# STM32H743 register map
File version: 2.4
CPU: CM7 r0p1, little endian, MPU, FPU, 4 interrupt priority bits
Registers are 32-bit, read-write, reset 0x0 unless marked. A register's access mark holds for its fields unless they carry their own. Offsets are from the block's base; [hi:lo] are bit positions.

## QUADSPI
Base 0x52005000
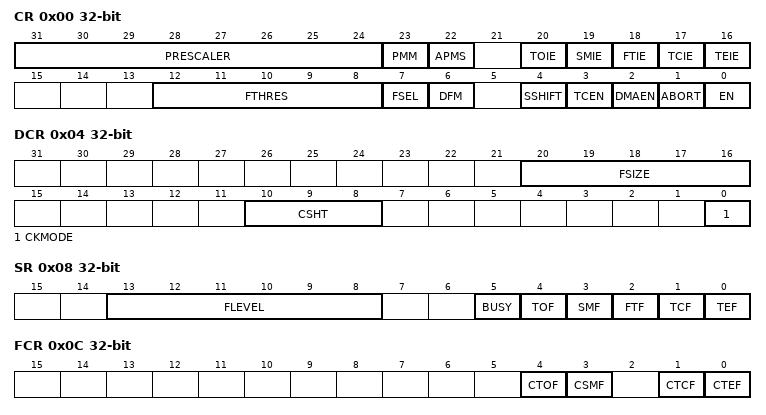
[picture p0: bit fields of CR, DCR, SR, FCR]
0x00 CR — QUADSPI 控制寄存器
  [31:24] PRESCALER — 时钟预分频器
  [23] PMM — 轮询匹配模式 该位指示在自动轮询模式期间用于确定匹配的方法。该位只能在 BUSY = 0 时修改。
  [22] APMS — 自动轮询模式停止 该位决定匹配后是否停止自动轮询。该位只能在 BUSY = 0 时修改。
  [20] TOIE — 超时中断使能 该位使能超时中断。
  [19] SMIE — 状态匹配中断使能 该位使能状态匹配中断。
  [18] FTIE — FIFO 阈值中断使能 该位使能 FIFO 阈值中断。
  [17] TCIE — 传输完成中断使能 该位使能传输完成中断。
  [16] TEIE — 传输错误中断使能 该位使能传输错误中断。
  [12:8] FTHRES — FIFO 阈值级别 在间接模式下，定义 FIFO 中触发 FIFO 阈值标志（FTF，QUADSPI_SR[2]）置位的字节阈值数。在间接写模式（FMODE = 00）下：...... 在间接读模式（FMODE = 01）下：...... 如果 DMAEN = 1，则在更改 FTHRES 值之前必须先禁用相应通道的 DMA 控制器。
  [7] FSEL — Flash 存储器选择 该位在单 Flash 模式（DFM = 0）下选择要寻址的 Flash 存储器。该位只能在 BUSY = 0 时修改。当 DFM = 1 时该位被忽略。
  [6] DFM — 双 Flash 模式 该位激活双 Flash 模式，即同时使用两个外部 Flash 存储器，使吞吐量和容量翻倍。该位只能在 BUSY = 0 时修改。
  [4] SSHIFT — 采样偏移 默认情况下，QUADSPI 在 Flash 存储器驱动数据后的 1/2 个 CLK 周期处采样数据。该位允许延迟采样数据，以补偿外部信号延迟。固件必须确保在 DDR 模式下（DDRM = 1）SSHIFT = 0。该字段只能在 BUSY = 0 时修改。
  [3] TCEN — 超时计数器使能 该位仅在选择了存储器映射模式（FMODE = 11）时有效。激活该位后，如果在指定时间内没有发生访问，片选信号（nCS）将被释放（从而降低功耗），该时间由 TIMEOUT[15:0]（QUADSPI_LPTR）定义。使能超时计数器。默认情况下，QUADSPI 不会停止其预取操作，即使长时间没有对 Flash 存储器的访问，仍会保持上一次读操作有效，nCS 维持低电平。由于 Flash 存储器在 nCS 保持低电平时功耗较高，应用程序可能需要激活超时计数器（TCEN = 1，QUADSPI_CR[3]），以便在 FIFO 被预取数据填满后，若在 TIMEOUT[15:0]（QUADSPI_LPTR）个周期内没有发生访问，则释放 nCS。该位只能在 BUSY = 0 时修改。
  [2] DMAEN — DMA 使能 在间接模式下，可通过 QUADSPI_DR 寄存器使用 DMA 输入或输出数据。当 FIFO 阈值标志 FTF 置位时，将启动 DMA 传输。
  [1] ABORT — 中止请求 该位中止正在进行的命令序列。中止完成后自动复位。该位会停止当前传输。在轮询模式或存储器映射模式下，该位还会复位 APM 位或 DM 位。
  [0] EN — 使能 使能 QUADSPI。
0x04 DCR — QUADSPI 器件配置寄存器
  [20:16] FSIZE — Flash 存储器容量 该字段使用以下公式定义外部存储器的容量：Flash 存储器的字节数 = 2[FSIZE+1]。FSIZE + 1 实际上是寻址 Flash 存储器所需的地址位数。在间接模式下，Flash 存储器容量最大可达 4GB（使用 32 位寻址），但在存储器映射模式下，可寻址空间限制为 256MB。如果 DFM = 1，FSIZE 表示两个 Flash 存储器的总容量。该字段只能在 BUSY = 0 时修改。
  [10:8] CSHT — 片选高电平时间 CSHT + 1 定义了向 Flash 存储器发出的命令之间，片选信号（nCS）必须保持高电平的最小 CLK 周期数。...... 该字段只能在 BUSY = 0 时修改。
  [0] CKMODE — 指示 CLK 在命令之间所处的电平
0x08 SR ro — QUADSPI 状态寄存器
  [13:8] FLEVEL — FIFO 级别 该字段给出 FIFO 中当前保存的有效字节数。FIFO 为空时 FLEVEL = 0，满时为 16。在存储器映射模式和自动状态轮询模式下，FLEVEL 为零。
  [5] BUSY — 忙标志 当操作正在进行时该位置位。当 Flash 存储器操作完成且 FIFO 为空时，该位自动清零。
  [4] TOF — 超时标志 发生超时时该位置位。向 CTOF 写入 1 可将其清零。
  [3] SMF — 状态匹配标志 在自动轮询模式下，当未掩码的接收数据与匹配寄存器（QUADSPI_PSMAR）中的对应位匹配时，该位置位。向 CSMF 写入 1 可将其清零。
  [2] FTF — FIFO 阈值标志 在间接模式下，当达到 FIFO 阈值时，或当 Flash 存储器读取完成后 FIFO 中仍有数据时，该位置位。一旦阈值条件不再满足，该位自动清零。在自动轮询模式下，每次读取状态寄存器时该位置位，读取数据寄存器时该位清零。
  [1] TCF — 传输完成标志 在间接模式下，当已传输完编程数量的数据时该位置位；或在任何模式下，当传输被中止时该位置位。向 CTCF 写入 1 可将其清零。
  [0] TEF — 传输错误标志 在间接模式下，当访问了无效地址时该位置位。向 CTEF 写入 1 可将其清零。
0x0C FCR — QUADSPI 标志清零寄存器
  [4] CTOF — 清除超时标志 写入 1 将清零 QUADSPI_SR 寄存器中的 TOF 标志。
  [3] CSMF — 清除状态匹配标志 写入 1 将清零 QUADSPI_SR 寄存器中的 SMF 标志。
  [1] CTCF — 清除传输完成标志 写入 1 将清零 QUADSPI_SR 寄存器中的 TCF 标志。
  [0] CTEF — 清除传输错误标志 写入 1 将清零 QUADSPI_SR 寄存器中的 TEF 标志。
0x10 DLR — QUADSPI 数据长度寄存器
  [31:0] DL — 数据长度 在间接模式和状态轮询模式下要获取的数据数量（值 + 1）。状态轮询模式下应使用不大于 3（表示 4 字节）的值。间接模式下的全 1 值表示未定义长度，此时 QUADSPI 将持续传输直到存储器末尾（由 FSIZE 定义）。0x0000_0000：传输 1 字节；0x0000_0001：传输 2 字节；0x0000_0002：传输 3 字节；0x0000_0003：传输 4 字节；......；0xFFFF_FFFD：传输 4,294,967,294（4G-2）字节；0xFFFF_FFFE：传输 4,294,967,295（4G-1）字节；0xFFFF_FFFF：未定义长度——传输所有字节直到 Flash 存储器末尾（由 FSIZE 定义）。如果 FSIZE = 0x1F，则无限继续读取。在双 Flash 模式（DFM = 1）下，即使向 DL[0] 写入 0，该位也会被强制置 1，从而确保每次访问传输偶数个字节。在存储器映射模式（FMODE = 10）下，该字段无效。该字段只能在 BUSY = 0 时写入。
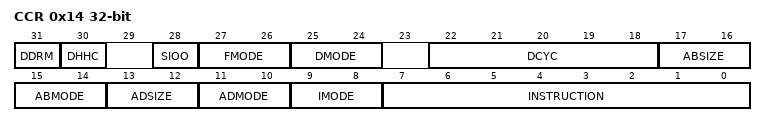
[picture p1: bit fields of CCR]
0x14 CCR — QUADSPI 通信配置寄存器
  [31] DDRM — 双倍数据速率模式 该位为地址阶段、交替字节阶段和数据阶段设置 DDR 模式：该字段只能在 BUSY = 0 时写入。
  [30] DHHC — DDR 保持 在 DDR 模式下，将数据输出延迟 QUADSPI 输出时钟周期的 1/4：此功能仅在 DDR 模式下有效。该字段只能在 BUSY = 0 时写入。
  [28] SIOO — 仅发送指令一次模式 参见第 15.3.11 节：仅发送指令一次（第 13 页）。当 IMODE = 00 时该位无效。该字段只能在 BUSY = 0 时写入。
  [27:26] FMODE — 功能模式 该字段定义 QUADSPI 的功能操作模式。如果 DMAEN 已为 1，则在更改 FMODE 值之前必须先禁用相应通道的 DMA 控制器。该字段只能在 BUSY = 0 时写入。
  [25:24] DMODE — 数据模式 该字段定义数据阶段的操作模式：该字段同时也决定了空周期阶段的操作模式。该字段只能在 BUSY = 0 时写入。
  [22:18] DCYC — 空周期数 该字段定义空周期阶段的持续时间。在 SDR 和 DDR 两种模式下，它指定 CLK 周期数（0-31）。该字段只能在 BUSY = 0 时写入。
  [17:16] ABSIZE — 交替字节大小 该位定义交替字节大小：该字段只能在 BUSY = 0 时写入。
  [15:14] ABMODE — 交替字节模式 该字段定义交替字节阶段的操作模式：该字段只能在 BUSY = 0 时写入。
  [13:12] ADSIZE — 地址大小 该位定义地址大小：该字段只能在 BUSY = 0 时写入。
  [11:10] ADMODE — 地址模式 该字段定义地址阶段的操作模式：该字段只能在 BUSY = 0 时写入。
  [9:8] IMODE — 指令模式 该字段定义指令阶段的操作模式：该字段只能在 BUSY = 0 时写入。
  [7:0] INSTRUCTION — 指令 要发送到外部 SPI 器件的指令。该字段只能在 BUSY = 0 时写入。
0x18 AR — QUADSPI 地址寄存器
  [31:0] ADDRESS — [31:0]：地址 要发送到外部 Flash 存储器的地址。当 BUSY = 0 或 FMODE = 11（存储器映射模式）时，对该字段的写入将被忽略。在双 Flash 模式下，ADDRESS[0] 自动强制为 0，因为地址应始终为偶数。
0x1C ABR — QUADSPI 交替字节寄存器
  [31:0] ALTERNATE — 交替字节 紧接地址之后发送到外部 SPI 器件的可选数据。该字段只能在 BUSY = 0 时写入。
0x20 DR — QUADSPI 数据寄存器
  [31:0] DATA — 数据 要发送到外部 SPI 器件或从外部 SPI 器件接收的数据。在间接写模式下，写入该寄存器的数据先存储在 FIFO 中，然后在数据阶段发送到 Flash 存储器。若 FIFO 过满，写操作将暂停，直到 FIFO 有足够空间容纳正在写入的数据量。在间接读模式下，读取该寄存器将（通过 FIFO）获取从 Flash 存储器接收的数据。若 FIFO 中没有读取操作所请求的字节数且 BUSY = 1，则读操作将暂停，直到有足够的数据或传输完成（以先发生者为准）。在自动轮询模式下，该寄存器包含从 Flash 存储器读取的最后数据（未掩码）。支持对该寄存器进行字、半字和字节访问。在间接写模式下，字节写入向 FIFO 添加 1 个字节，半字写入添加 2 个字节，字写入添加 4 个字节。类似地，在间接读模式下，字节读取从 FIFO 移除 1 个字节，半字读取移除 2 个字节，字读取移除 4 个字节。间接模式下的访问必须与该寄存器的低位对齐：字节读取必须读取 DATA[7:0]，半字读取必须读取 DATA[15:0]。
0x24 PSMKR — QUADSPI 轮询状态掩码寄存器
  [31:0] MASK — 状态掩码 在轮询模式下，对接收到的状态字节应用的掩码。对于位 n：该字段只能在 BUSY = 0 时写入。
0x28 PSMAR — QUADSPI 轮询状态匹配寄存器
  [31:0] MATCH — 状态匹配值 用于与掩码后的状态寄存器进行比较以获取匹配的值。该字段只能在 BUSY = 0 时写入。
0x2C PIR — QUADSPI 轮询间隔寄存器
  [15:0] INTERVAL — 轮询间隔 自动轮询阶段期间两次读取之间的 CLK 周期数。该字段只能在 BUSY = 0 时写入。
0x30 LPTR — QUADSPI 低功耗超时寄存器
  [15:0] TIMEOUT — 超时周期 在存储器映射模式下，每次访问后，QUADSPI 会预取后续字节并将其保存在 FIFO 中。该字段指示 FIFO 填满后，QUADSPI 等待多少个 CLK 周期才将 nCS 拉高，使 Flash 存储器进入低功耗状态。该字段只能在 BUSY = 0 时写入。
